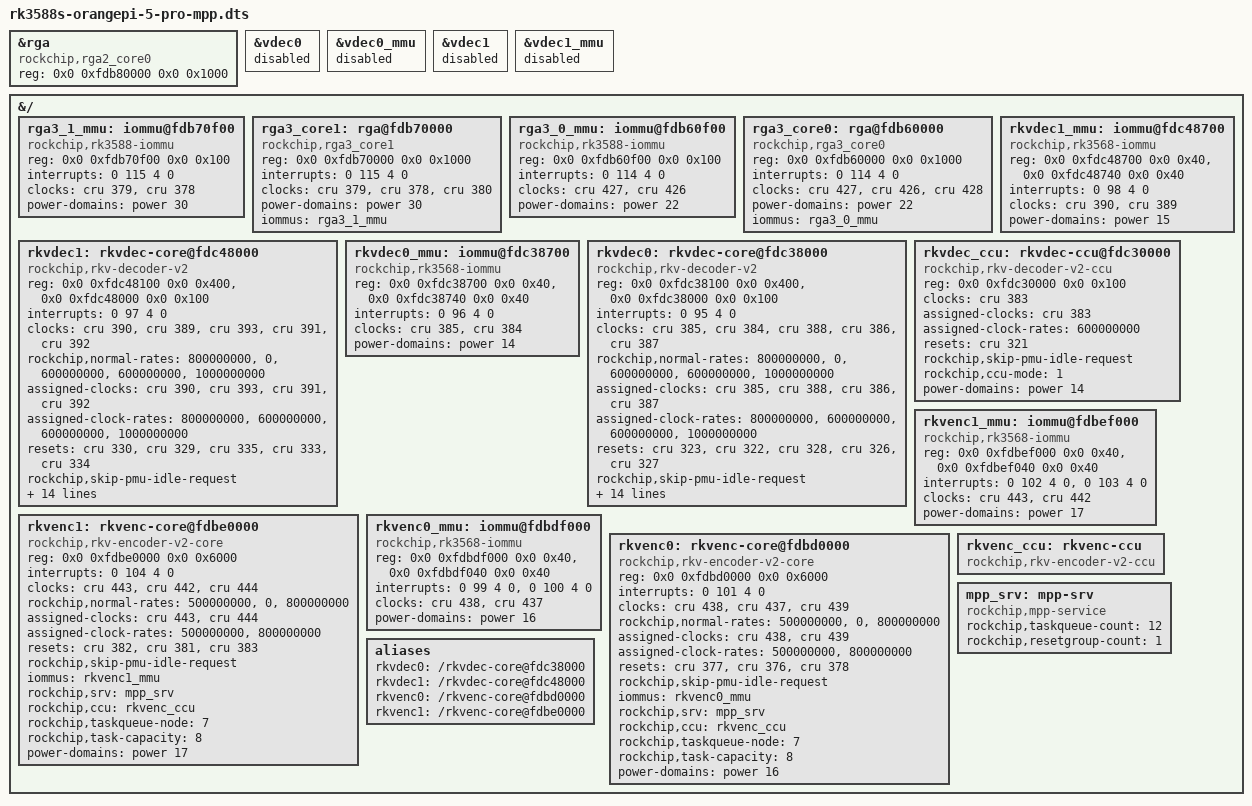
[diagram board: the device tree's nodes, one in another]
// 
// Generated by tools/overlays.sh from userpatches/.../dt/rk3588s-orangepi-5-pro-mpp.dtsi.
/dts-v1/;
/plugin/;
&rga {
 compatible = "rockchip,rga2_core0";
 reg = <0x0 0xfdb80000 0x0 0x1000>;
 interrupt-names = "rga2_irq";
 clock-names = "aclk_rga2", "hclk_rga2", "clk_rga2";
 status = "okay";
};
&vdec0 {
 status = "disabled";
};
&vdec0_mmu {
 status = "disabled";
};
&vdec1 {
 status = "disabled";
};
&vdec1_mmu {
 status = "disabled";
};
&{/} {
 rga3_1_mmu: iommu@fdb70f00 {
  compatible = "rockchip,rk3588-iommu", "rockchip,rk3568-iommu";
  reg = <0x0 0xfdb70f00 0x0 0x100>;
  interrupts = <0 115 4 0>;
  interrupt-names = "rga3_1_mmu";
  clocks = <&cru 379>, <&cru 378>;
  clock-names = "aclk", "iface";
  power-domains = <&power 30>;
  #iommu-cells = <0>;
  status = "okay";
 };
 rga3_core1: rga@fdb70000 {
  compatible = "rockchip,rga3_core1";
  reg = <0x0 0xfdb70000 0x0 0x1000>;
  interrupts = <0 115 4 0>;
  interrupt-names = "rga3_core1_irq";
  clocks = <&cru 379>, <&cru 378>,
    <&cru 380>;
  clock-names = "aclk_rga3_1", "hclk_rga3_1", "clk_rga3_1";
  power-domains = <&power 30>;
  iommus = <&rga3_1_mmu>;
  status = "okay";
 };
 rga3_0_mmu: iommu@fdb60f00 {
  compatible = "rockchip,rk3588-iommu", "rockchip,rk3568-iommu";
  reg = <0x0 0xfdb60f00 0x0 0x100>;
  interrupts = <0 114 4 0>;
  interrupt-names = "rga3_0_mmu";
  clocks = <&cru 427>, <&cru 426>;
  clock-names = "aclk", "iface";
  power-domains = <&power 22>;
  #iommu-cells = <0>;
  status = "okay";
 };
 rga3_core0: rga@fdb60000 {
  compatible = "rockchip,rga3_core0";
  reg = <0x0 0xfdb60000 0x0 0x1000>;
  interrupts = <0 114 4 0>;
  interrupt-names = "rga3_core0_irq";
  clocks = <&cru 427>, <&cru 426>,
    <&cru 428>;
  clock-names = "aclk_rga3_0", "hclk_rga3_0", "clk_rga3_0";
  power-domains = <&power 22>;
  iommus = <&rga3_0_mmu>;
  status = "okay";
 };
 rkvdec1_mmu: iommu@fdc48700 {
  compatible = "rockchip,rk3568-iommu";
  reg = <0x0 0xfdc48700 0x0 0x40>, <0x0 0xfdc48740 0x0 0x40>;
  interrupts = <0 98 4 0>;
  clocks = <&cru 390>, <&cru 389>;
  clock-names = "aclk", "iface";
  #iommu-cells = <0>;
  power-domains = <&power 15>;
  status = "okay";
 };
 rkvdec1: rkvdec-core@fdc48000 {
  compatible = "rockchip,rkv-decoder-v2";
  reg = <0x0 0xfdc48100 0x0 0x400>, <0x0 0xfdc48000 0x0 0x100>;
  reg-names = "regs", "link";
  interrupts = <0 97 4 0>;
  clocks = <&cru 390>, <&cru 389>,
    <&cru 393>, <&cru 391>,
    <&cru 392>;
  clock-names = "aclk_vcodec", "hclk_vcodec", "clk_core",
         "clk_cabac", "clk_hevc_cabac";
  rockchip,normal-rates = <800000000>, <0>, <600000000>,
     <600000000>, <1000000000>;
  assigned-clocks = <&cru 390>, <&cru 393>,
      <&cru 391>, <&cru 392>;
  assigned-clock-rates = <800000000>, <600000000>,
           <600000000>, <1000000000>;
  resets = <&cru 330>, <&cru 329>,
    <&cru 335>, <&cru 333>,
    <&cru 334>;
  reset-names = "video_a", "video_h", "video_core", "video_cabac",
         "video_hevc_cabac";
  rockchip,skip-pmu-idle-request;
  rockchip,vpu-reset-smc;
  iommus = <&rkvdec1_mmu>;
  rockchip,srv = <&mpp_srv>;
  rockchip,ccu = <&rkvdec_ccu>;
  rockchip,core-mask = <0x00020002>;
  rockchip,task-capacity = <16>;
  rockchip,taskqueue-node = <9>;
  rockchip,sram = <&vdec1_sram>;
  rockchip,rcb-iova = <0xffe00000 0x100000>;
  rockchip,rcb-info = <136 24576>, <137 49152>, <141 90112>,
        <140 49152>, <139 180224>, <133 49152>,
        <134 8192>, <135 4352>, <138 13056>, <142 291584>;
  rockchip,rcb-min-width = <512>;
  power-domains = <&power 15>;
  status = "okay";
 };
 rkvdec0_mmu: iommu@fdc38700 {
  compatible = "rockchip,rk3568-iommu";
  reg = <0x0 0xfdc38700 0x0 0x40>, <0x0 0xfdc38740 0x0 0x40>;
  interrupts = <0 96 4 0>;
  clocks = <&cru 385>, <&cru 384>;
  clock-names = "aclk", "iface";
  #iommu-cells = <0>;
  power-domains = <&power 14>;
  status = "okay";
 };
 rkvdec0: rkvdec-core@fdc38000 {
  compatible = "rockchip,rkv-decoder-v2";
  reg = <0x0 0xfdc38100 0x0 0x400>, <0x0 0xfdc38000 0x0 0x100>;
  reg-names = "regs", "link";
  interrupts = <0 95 4 0>;
  clocks = <&cru 385>, <&cru 384>,
    <&cru 388>, <&cru 386>,
    <&cru 387>;
  clock-names = "aclk_vcodec", "hclk_vcodec", "clk_core",
         "clk_cabac", "clk_hevc_cabac";
  rockchip,normal-rates = <800000000>, <0>, <600000000>,
     <600000000>, <1000000000>;
  assigned-clocks = <&cru 385>, <&cru 388>,
      <&cru 386>, <&cru 387>;
  assigned-clock-rates = <800000000>, <600000000>,
           <600000000>, <1000000000>;
  resets = <&cru 323>, <&cru 322>,
    <&cru 328>, <&cru 326>,
    <&cru 327>;
  reset-names = "video_a", "video_h", "video_core", "video_cabac",
         "video_hevc_cabac";
  rockchip,skip-pmu-idle-request;
  rockchip,vpu-reset-smc;
  iommus = <&rkvdec0_mmu>;
  rockchip,srv = <&mpp_srv>;
  rockchip,ccu = <&rkvdec_ccu>;
  rockchip,core-mask = <0x00010001>;
  rockchip,task-capacity = <16>;
  rockchip,taskqueue-node = <9>;
  rockchip,sram = <&vdec0_sram>;
  rockchip,rcb-iova = <0xfff00000 0x100000>;
  rockchip,rcb-info = <136 24576>, <137 49152>, <141 90112>,
        <140 49152>, <139 180224>, <133 49152>,
        <134 8192>, <135 4352>, <138 13056>, <142 291584>;
  rockchip,rcb-min-width = <512>;
  power-domains = <&power 14>;
  status = "okay";
 };
 rkvdec_ccu: rkvdec-ccu@fdc30000 {
  compatible = "rockchip,rkv-decoder-v2-ccu";
  reg = <0x0 0xfdc30000 0x0 0x100>;
  reg-names = "ccu";
  clocks = <&cru 383>;
  clock-names = "aclk_ccu";
  assigned-clocks = <&cru 383>;
  assigned-clock-rates = <600000000>;
  resets = <&cru 321>;
  reset-names = "video_ccu";
  rockchip,skip-pmu-idle-request;
  rockchip,ccu-mode = <1>;
  power-domains = <&power 14>;
  status = "okay";
 };
 rkvenc1_mmu: iommu@fdbef000 {
  compatible = "rockchip,rk3568-iommu";
  reg = <0x0 0xfdbef000 0x0 0x40>, <0x0 0xfdbef040 0x0 0x40>;
  interrupts = <0 102 4 0>,
        <0 103 4 0>;
  clocks = <&cru 443>, <&cru 442>;
  clock-names = "aclk", "iface";
  #iommu-cells = <0>;
  power-domains = <&power 17>;
  status = "okay";
 };
 rkvenc1: rkvenc-core@fdbe0000 {
  compatible = "rockchip,rkv-encoder-v2-core";
  reg = <0x0 0xfdbe0000 0x0 0x6000>;
  interrupts = <0 104 4 0>;
  clocks = <&cru 443>, <&cru 442>,
    <&cru 444>;
  clock-names = "aclk_vcodec", "hclk_vcodec", "clk_core";
  rockchip,normal-rates = <500000000>, <0>, <800000000>;
  assigned-clocks = <&cru 443>, <&cru 444>;
  assigned-clock-rates = <500000000>, <800000000>;
  resets = <&cru 382>, <&cru 381>,
    <&cru 383>;
  reset-names = "video_a", "video_h", "video_core";
  rockchip,skip-pmu-idle-request;
  iommus = <&rkvenc1_mmu>;
  rockchip,srv = <&mpp_srv>;
  rockchip,ccu = <&rkvenc_ccu>;
  rockchip,taskqueue-node = <7>;
  rockchip,task-capacity = <8>;
  power-domains = <&power 17>;
  status = "okay";
 };
 rkvenc0_mmu: iommu@fdbdf000 {
  compatible = "rockchip,rk3568-iommu";
  reg = <0x0 0xfdbdf000 0x0 0x40>, <0x0 0xfdbdf040 0x0 0x40>;
  interrupts = <0 99 4 0>,
        <0 100 4 0>;
  clocks = <&cru 438>, <&cru 437>;
  clock-names = "aclk", "iface";
  #iommu-cells = <0>;
  power-domains = <&power 16>;
  status = "okay";
 };
 rkvenc0: rkvenc-core@fdbd0000 {
  compatible = "rockchip,rkv-encoder-v2-core";
  reg = <0x0 0xfdbd0000 0x0 0x6000>;
  interrupts = <0 101 4 0>;
  clocks = <&cru 438>, <&cru 437>,
    <&cru 439>;
  clock-names = "aclk_vcodec", "hclk_vcodec", "clk_core";
  rockchip,normal-rates = <500000000>, <0>, <800000000>;
  assigned-clocks = <&cru 438>, <&cru 439>;
  assigned-clock-rates = <500000000>, <800000000>;
  resets = <&cru 377>, <&cru 376>,
    <&cru 378>;
  reset-names = "video_a", "video_h", "video_core";
  rockchip,skip-pmu-idle-request;
  iommus = <&rkvenc0_mmu>;
  rockchip,srv = <&mpp_srv>;
  rockchip,ccu = <&rkvenc_ccu>;
  rockchip,taskqueue-node = <7>;
  rockchip,task-capacity = <8>;
  power-domains = <&power 16>;
  status = "okay";
 };
 rkvenc_ccu: rkvenc-ccu {
  compatible = "rockchip,rkv-encoder-v2-ccu";
  status = "okay";
 };
 mpp_srv: mpp-srv {
  compatible = "rockchip,mpp-service";
  rockchip,taskqueue-count = <12>;
  rockchip,resetgroup-count = <1>;
  status = "okay";
 };
 aliases {
  rkvdec0 = "/rkvdec-core@fdc38000";
  rkvdec1 = "/rkvdec-core@fdc48000";
  rkvenc0 = "/rkvenc-core@fdbd0000";
  rkvenc1 = "/rkvenc-core@fdbe0000";
 };
};
&rkvdec0_mmu {
 status = "okay";
};
&rkvdec1_mmu {
 status = "okay";
};
